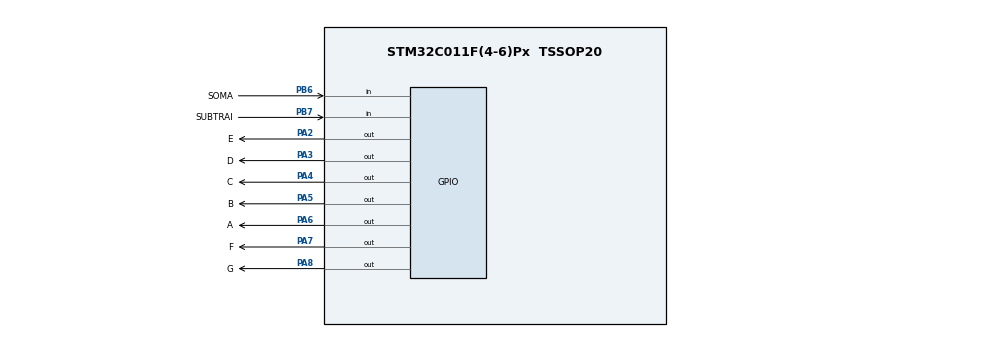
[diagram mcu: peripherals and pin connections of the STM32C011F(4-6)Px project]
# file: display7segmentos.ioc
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Mcu.Family=STM32C0
Mcu.Name=STM32C011F(4-6)Px
Mcu.Package=TSSOP20
PA13.Mode=Serial_Wire
PA13.Signal=DEBUG_SWDIO
PA14-BOOT0.Mode=Serial_Wire
PA14-BOOT0.Signal=DEBUG_SWCLK
PA2.GPIO_Label=E
PA2.Signal=GPIO_Output
PA3.GPIO_Label=D
PA3.Signal=GPIO_Output
PA4.GPIO_Label=C
PA4.Signal=GPIO_Output
PA5.GPIO_Label=B
PA5.Signal=GPIO_Output
PA6.GPIO_Label=A
PA6.Signal=GPIO_Output
PA7.GPIO_Label=F
PA7.Signal=GPIO_Output
PA8.GPIO_Label=G
PA8.Signal=GPIO_Output
PB6.GPIO_Label=SOMA
PB6.GPIO_PuPd=GPIO_PULLUP
PB6.Signal=GPIO_Input
PB7.GPIO_Label=SUBTRAI
PB7.GPIO_PuPd=GPIO_PULLUP
PB7.Signal=GPIO_Input
ProjectManager.HeapSize=0x200
ProjectManager.StackSize=0x400
ProjectManager.TargetToolchain=STM32CubeIDE
RCC.ADCFreq_Value=48000000
RCC.AHBFreq_Value=48000000
RCC.CortexFreq_Value=48000000
RCC.EXTERNAL_CLOCK_VALUE=12288000
RCC.HCLKFreq_Value=48000000
RCC.HSE_VALUE=8000000
RCC.HSISYSCLKDivider=RCC_HSI_DIV1
RCC.HSI_VALUE=48000000
RCC.LSE_VALUE=32768
RCC.SYSCLKFreq_VALUE=48000000
board=custom

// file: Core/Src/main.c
/* USER CODE BEGIN Header */
/**
  ******************************************************************************
  * @file           : main.c
  * @brief          : Main program body
  ******************************************************************************
  * @attention
  *
  * Copyright (c) 2024 STMicroelectronics.
  * All rights reserved.
  *
  * This software is licensed under terms that can be found in the LICENSE file
  * in the root directory of this software component.
  * If no LICENSE file comes with this software, it is provided AS-IS.
  *
  ******************************************************************************
  */
/* USER CODE END Header */
#include "main.h"

void SystemClock_Config(void);
static void MX_GPIO_Init(void);
void numero(uint32_t a, uint32_t b,uint32_t c,uint32_t d,uint32_t e, uint32_t f, uint32_t g);
void atualizaDisplay(int valor);
int debounceBotao(GPIO_TypeDef* GPIOx, uint16_t GPIO_Pin);

int main(void)
{

  /* MCU Configuration--------------------------------------------------------*/

  /* Reset of all peripherals, Initializes the Flash interface and the Systick. */
  HAL_Init();

  /* Configure the system clock */
  SystemClock_Config();

  /* Initialize all configured peripherals */
  MX_GPIO_Init();
  /* USER CODE BEGIN 2 */
  int valor = 0;
  atualizaDisplay(valor);
  /* USER CODE END 2 */

  /* Infinite loop */
  while (1)
  {
    /* USER CODE BEGIN 3 */
	 if (debounceBotao(GPIOB, SOMA_Pin)){
         valor = (valor + 1) % 10; //assegurar que permaneça dentro do intervalo de 0 a 9
		 atualizaDisplay(valor);
	 }

	 if (debounceBotao(GPIOB, SUBTRAI_Pin)){
		  valor = (valor - 1 + 10) % 10; //assegurar que permaneça dentro do intervalo de 0 a 9
		  atualizaDisplay(valor);
	 }
  }
  /* USER CODE END 3 */
}

void numero(uint32_t a, uint32_t b,uint32_t c,uint32_t d,uint32_t e, uint32_t f, uint32_t g){
	HAL_GPIO_WritePin(GPIOA, A_Pin, a);
	HAL_GPIO_WritePin(GPIOA, B_Pin, b);
	HAL_GPIO_WritePin(GPIOA, C_Pin, c);
	HAL_GPIO_WritePin(GPIOA, D_Pin, d);
	HAL_GPIO_WritePin(GPIOA, E_Pin, e);
	HAL_GPIO_WritePin(GPIOA, F_Pin, f);
	HAL_GPIO_WritePin(GPIOA, G_Pin, g);
}

void atualizaDisplay(int valor)
{
    // Configurações dos segmentos para cada dígito de 0 a 9
    switch(valor)
    {
        case 0: numero(1, 1, 1, 1, 1, 1, 0); break;
        case 1: numero(0, 1, 1, 0, 0, 0, 0); break;
        case 2: numero(1, 1, 0, 1, 1, 0, 1); break;
        case 3: numero(1, 1, 1, 1, 0, 0, 1); break;
        case 4: numero(0, 1, 1, 0, 0, 1, 1); break;
        case 5: numero(1, 0, 1, 1, 0, 1, 1); break;
        case 6: numero(1, 0, 1, 1, 1, 1, 1); break;
        case 7: numero(1, 1, 1, 0, 0, 0, 0); break;
        case 8: numero(1, 1, 1, 1, 1, 1, 1); break;
        case 9: numero(1, 1, 1, 1, 0, 1, 1); break;
    }
}

int debounceBotao(GPIO_TypeDef* GPIOx, uint16_t GPIO_Pin)
{
    uint32_t debounce_inicio = HAL_GetTick();
    // Aguarda até que o botão seja liberado
    while (HAL_GPIO_ReadPin(GPIOx, GPIO_Pin) == GPIO_PIN_RESET)
    {
        if (HAL_GetTick() - debounce_inicio >= 50) // Espera 50ms
        {
            // Botão pressionado por tempo suficiente
            while (HAL_GPIO_ReadPin(GPIOx, GPIO_Pin) == GPIO_PIN_RESET); // Espera o botão ser solto
            return 1; // Retorna verdadeiro
        }
    }

    return 0; // Retorna falso se o botão não foi pressionado por tempo suficiente
}
void SystemClock_Config(void)
{
  RCC_OscInitTypeDef RCC_OscInitStruct = {0};
  RCC_ClkInitTypeDef RCC_ClkInitStruct = {0};

  /** Initializes the RCC Oscillators according to the specified parameters
  * in the RCC_OscInitTypeDef structure.
  */
  RCC_OscInitStruct.OscillatorType = RCC_OSCILLATORTYPE_HSI;
  RCC_OscInitStruct.HSIState = RCC_HSI_ON;
  RCC_OscInitStruct.HSIDiv = RCC_HSI_DIV1;
  RCC_OscInitStruct.HSICalibrationValue = RCC_HSICALIBRATION_DEFAULT;
  if (HAL_RCC_OscConfig(&RCC_OscInitStruct) != HAL_OK)
  {
    Error_Handler();
  }

  /** Initializes the CPU, AHB and APB buses clocks
  */
  RCC_ClkInitStruct.ClockType = RCC_CLOCKTYPE_HCLK|RCC_CLOCKTYPE_SYSCLK
                              |RCC_CLOCKTYPE_PCLK1;
  RCC_ClkInitStruct.SYSCLKSource = RCC_SYSCLKSOURCE_HSI;
  RCC_ClkInitStruct.SYSCLKDivider = RCC_SYSCLK_DIV1;
  RCC_ClkInitStruct.AHBCLKDivider = RCC_HCLK_DIV1;
  RCC_ClkInitStruct.APB1CLKDivider = RCC_APB1_DIV1;

  if (HAL_RCC_ClockConfig(&RCC_ClkInitStruct, FLASH_LATENCY_1) != HAL_OK)
  {
    Error_Handler();
  }
}

static void MX_GPIO_Init(void)
{
  GPIO_InitTypeDef GPIO_InitStruct = {0};

  /* GPIO Ports Clock Enable */
  __HAL_RCC_GPIOB_CLK_ENABLE();
  __HAL_RCC_GPIOA_CLK_ENABLE();

  /*Configure GPIO pin Output Level */
  HAL_GPIO_WritePin(GPIOA, E_Pin|D_Pin|C_Pin|B_Pin
                          |A_Pin|F_Pin|G_Pin, GPIO_PIN_RESET);

  /*Configure GPIO pins : SUBTRAI_Pin SOMA_Pin */
  GPIO_InitStruct.Pin = SUBTRAI_Pin|SOMA_Pin;
  GPIO_InitStruct.Mode = GPIO_MODE_INPUT;
  GPIO_InitStruct.Pull = GPIO_PULLUP;
  HAL_GPIO_Init(GPIOB, &GPIO_InitStruct);

  /*Configure GPIO pins : E_Pin D_Pin C_Pin B_Pin
                           A_Pin F_Pin G_Pin */
  GPIO_InitStruct.Pin = E_Pin|D_Pin|C_Pin|B_Pin
                          |A_Pin|F_Pin|G_Pin;
  GPIO_InitStruct.Mode = GPIO_MODE_OUTPUT_PP;
  GPIO_InitStruct.Pull = GPIO_NOPULL;
  GPIO_InitStruct.Speed = GPIO_SPEED_FREQ_LOW;
  HAL_GPIO_Init(GPIOA, &GPIO_InitStruct);

}

void Error_Handler(void)
{
  __disable_irq();
  while (1)
  {
  }
}
